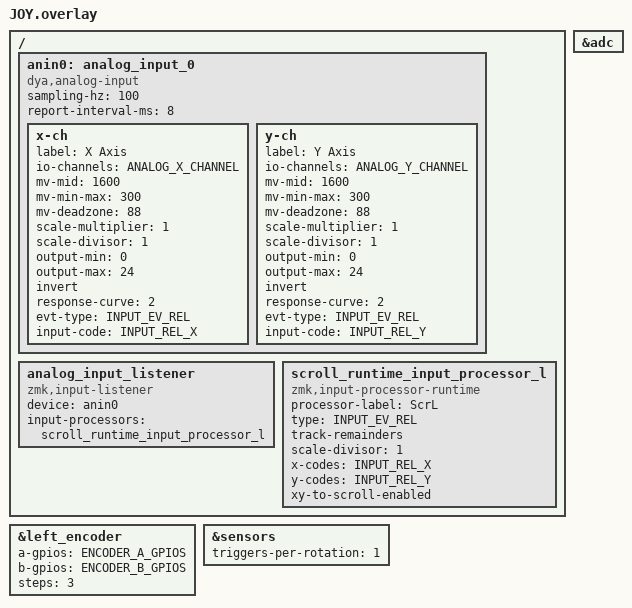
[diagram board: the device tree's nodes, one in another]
#include <zephyr/dt-bindings/input/input-event-codes.h>
#include <input/processors.dtsi>
#include <dt-bindings/zmk/input_transform.h>
#include <dt-bindings/zmk/keys.h>

/ {
    anin0: analog_input_0 {
        compatible = "dya,analog-input";
        sampling-hz = <100>;
        report-interval-ms = <8>;
        x-ch {
            label = "X Axis";
            io-channels = ANALOG_X_CHANNEL;
            mv-mid = <1600>;
            mv-min-max = <300>;
            mv-deadzone = <88>;
            scale-multiplier = <1>;
            scale-divisor = <1>;
            output-min = <0>;
            output-max = <24>;
            invert;
            response-curve = <2>;
            evt-type = <INPUT_EV_REL>;
            input-code = <INPUT_REL_X>;
        };
        y-ch {
            label = "Y Axis";
            io-channels = ANALOG_Y_CHANNEL;
            mv-mid = <1600>;
            mv-min-max = <300>;
            mv-deadzone = <88>;
            scale-multiplier = <1>;
            scale-divisor = <1>;
            output-min = <0>;
            output-max = <24>;
            invert;
            response-curve = <2>;
            evt-type = <INPUT_EV_REL>;
            input-code = <INPUT_REL_Y>;
        };
    };

    analog_input_listener {
        status = "okay";
        compatible = "zmk,input-listener";
        device = <&anin0>;
        input-processors = <&scroll_runtime_input_processor_l>;
    };

    scroll_runtime_input_processor_l: scroll_runtime_input_processor_l {
        compatible = "zmk,input-processor-runtime";
        processor-label = "ScrL";
        type = <INPUT_EV_REL>;
        track-remainders;
        scale-divisor = <1>;
        #input-processor-cells = <0>;
    };
};

&adc {
    status = "okay";
};

&left_encoder {
    a-gpios = ENCODER_A_GPIOS;
    b-gpios = ENCODER_B_GPIOS;
    steps = <3>;
    status = "okay";
};

&sensors {
    triggers-per-rotation = <1>;
};

&scroll_runtime_input_processor_l {
    x-codes = <INPUT_REL_X>;
    y-codes = <INPUT_REL_Y>;
    xy-to-scroll-enabled;
};
